# H5 register map
Vendor: Allwinner; Series: H5; File version: 0.1
CPU: 0, little endian, MPU, no FPU, 0 interrupt priority bits
Registers are 32-bit, read-write, reset 0x0 unless marked. A register's access mark holds for its fields unless they carry their own. Offsets are from the block's base; [hi:lo] are bit positions; lines under a group give offsets from that group; {n}, {i} and the like mark numbered series.

## TSC
Base 0x01C06000
Same registers: TSG 0x01C06040, TSF0 0x01C06100, TSD0 0x01C06180, TSF1 0x01C06200, TSD1 0x01C06280, TSF2 0x01C06300, TSD2 0x01C06380, TSF3 0x01C06400, TSD3 0x01C06480, TSF4 0x01C06500, TSD4 0x01C06580
0x00 TSC group
  0x00 TSC_CTLR reset not defined — TSC Control Register
  0x04 TSC_STAR reset not defined — TSC Status Register
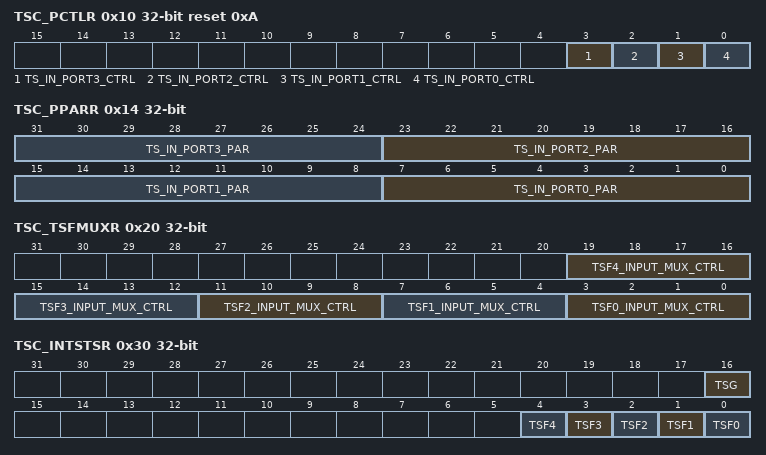
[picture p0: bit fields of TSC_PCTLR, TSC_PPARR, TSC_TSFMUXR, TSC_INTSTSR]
  0x10 TSC_PCTLR reset 0xA — TSC Port Control Register
    [3] TS_IN_PORT3_CTRL — TSInPort3Ctrl TS Input Port3 Control 0: Reserved 1: SSI
      1=SSI
    [2] TS_IN_PORT2_CTRL — TSInPort2Ctrl TS Input Port2 Control 0: SPI 1: SSI
      0=SPI; 1=SSI
    [1] TS_IN_PORT1_CTRL — TSInPort1Ctrl TS Input Port1 Control 0: Reserved 1: SSI
      1=SSI
    [0] TS_IN_PORT0_CTRL — TSInPort0Ctrl TS Input Port0 Control 0: SPI 1: SSI
      0=SPI; 1=SSI
  0x14 TSC_PPARR — TSC Port Parameter Register
    [8n+7:8n] TS_IN_PORT{n}_PAR (n=0..3) — TSInPort{n}Par TS Input Port{n} Parameters Bit Definition 7:5 Reserved 4 SSI data order 0: MSB first for one byte data 1: LSB first for one byte data 3 CLOCK signal polarity 0: Rise edge capturing 1: Fall edge capturing 2 ERROR signal polarity 0: High level active 1: Low level active 1 DVALID signal polarity 0: High level active 1: Low level active 0 PSYNC signal polarity 0: High level active 1: Low level active
  0x20 TSC_TSFMUXR — TSC TSF Input Multiplex Control Register
    [19:16] TSF4_INPUT_MUX_CTRL — TSF4InputMuxCtrl TSF4 Input Multiplex Control 0000: Data from TSG 0001: Data from TS IN Port0 0010: Data from TS IN Port1 0011: Data from TS IN Port2 0100: Data from TS IN Port3 Others: Reserved
    [15:12] TSF3_INPUT_MUX_CTRL — TSF3InputMuxCtrl TSF3 Input Multiplex Control 0000: Data from TSG 0001: Data from TS IN Port2 0010: Data from TS IN Port3 Others: Reserved
    [11:8] TSF2_INPUT_MUX_CTRL — TSF2InputMuxCtrl TSF2 Input Multiplex Control 0000: Data from TSG 0001: Data from TS IN Port2 Others: Reserved
      0=Data_from_TSG; 1=Data from TS IN Port2 Others: Reserved
    [7:4] TSF1_INPUT_MUX_CTRL — TSF1InputMuxCtrl TSF1 Input Multiplex Control 0000: Data from TSG 0001: Data from TS IN Port0 0010: Data from TS IN Port1 Others: Reserved
    [3:0] TSF0_INPUT_MUX_CTRL — TSF0InputMuxCtrl TSF0 Input Multiplex Control 0000: Data from TSG 0001: Data from TS IN Port0 Others: Reserved
      0=Data_from_TSG; 1=Data from TS IN Port0 Others: Reserved
  0x28 TSC_OUTMUXR reset not defined — TSC Port Output Multiplex Control Register
  0x30 TSC_INTSTSR — TSC Interrupt Status Register
    [16] TSG ro — Interrupt Global Status When all TSG interrupt status bits are cleared,the bit will be cleared by hardware.
    [n] TSF{n} ro (n=0..4) — Interrupt Global Status When all TSF{n} interrupt status bits are cleared,the bit will be cleared by hardware.
0x00 TSD group
  0x00 TSD_CTLR — TSD Control Register
    [1:0] DESC_ARITH — DescArith Descramble Arithmetic 00: DVB CSA V1.1 Others: Reserved
      0=DVB (DVB CSA V1.1 Others: Reserved)
  0x04 TSD_STAR reset not defined — TSD Status Register
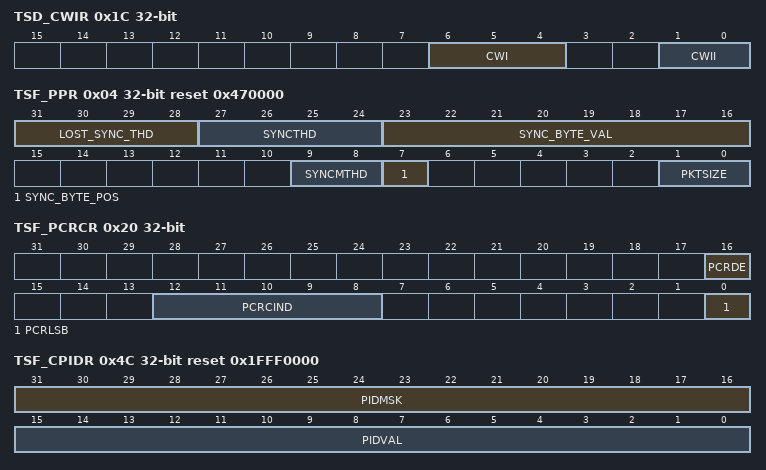
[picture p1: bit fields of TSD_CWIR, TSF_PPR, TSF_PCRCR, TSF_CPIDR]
  0x1C TSD_CWIR — TSD Control Word Index Register
    [6:4] CWI — Control Word Index This value is the Control index for Control word access. Range is from 0x0 to 0x7.
    [1:0] CWII — Control Word Internal Index 00: Odd Control Word Low 32-bit, OCW[31:0] 01: Odd Control Word High 32-bit, OCW[63:32] 10: Even Control Word Low 32-bit, ECW[31:0] 11: Even Control Word High 32-bit, ECW[63:0]
      0=Odd Control Word Low 32-bit, OCW[31:0]; 1=Odd Control Word High 32-bit, OCW[63:32]; 2=Even Control Word Low 32-bit, ECW[31:0]; 3=Even Control Word High 32-bit, ECW[63:0]
  0x20 TSD_CWR — TSD Control Word Register
    [31:0] CWD — Content of Control Word corresponding to the TSD_CWIR value
0x00 TSF group
  0x04 TSF_PPR reset 0x470000 — TSF Packet Parameter Register
    [31:28] LOST_SYNC_THD — LostSyncThd Lost Sync Packet Threshold It is used for packet sync lost by checking the value of sync byte.
    [27:24] SYNCTHD — SyncThd Sync Packet Threshold It is used for packet sync by checking the value of sync byte.
    [23:16] SYNC_BYTE_VAL — SyncByteVal Sync Byte Value This is the value of sync byte used in the TS Packet.
    [9:8] SYNCMTHD — SyncMthd Packet Sync Method 00: By PSYNC signal 01: By Sync byte 10: By both PSYNC and Sync Byte 11: Reserved
      0=By PSYNC signal; 1=By Sync byte; 2=By both PSYNC and Sync Byte
    [7] SYNC_BYTE_POS — SyncBytePos Sync Byte Position 0: The 1st byte position 1: The 5th byte position Note: This bit is only used for 192 bytes packet size.
      0=_1st (The 1st byte position); 1=_5th (The 5th byte position Note: This bit is only used for 192 bytes packet size.)
    [1:0] PKTSIZE — PktSize Packet Size Byte Size for one TS packet 00: 188 bytes 01: 192 bytes 10: 204 bytes 11: Reserved
      0=188 bytes; 1=192 bytes; 2=204 bytes
  0x10 TSF_DIER — TSF DMA Interrupt Enable Register
    [31:0] DMAIE — DMA Interrupt Enable DMA interrupt enable bits for channel 0~31.
  0x14 TSF_OIER — TSF Overlap Interrupt Enable Register
    [31:0] OLPIE — Overlap Interrupt Enable Overlap interrupt enable bits for channel 0~31.
  0x18 TSF_DISR — TSF DMA Interrupt Status Register
    [31:0] DMAIS — DMA Interrupt Status DMA interrupt status bits for channel 0~31. Set by hardware, and write 1 to clear it by software. When both these bits and the corresponding DMA Interrupt Enable bits set, the TSF interrupt will generate.
  0x1C TSF_OISR — TSF Overlap Interrupt Status Register
    [31:0] OLPIS — Overlap Interrupt Status Overlap interrupt status bits for channel 0~31. Set ha d a e, a d a e lea ed soft a e iti g . When both these bits and the corresponding Overlap Interrupt Enable bits set, the TSF interrupt will generate.
  0x20 TSF_PCRCR — TSF PCR Control Register
    [16] PCRDE — PCR Detecting Enable 0: Disable 1: Enable
      0=Disable; 1=Enable
    [12:8] PCRCIND — Channel Index m for detecting PCR packet (m from 0 to 31)
    [0] PCRLSB ro — PCR Contest LSB 1 bit PCR[0]
  0x24 TSF_PCRDR — TSF PCR Data Register
    [31:0] PCRMSB ro — PCR Data High 32 bits PCR[33:1]
  0x30 TSF_CENR — TSF Channel Enable Register
    [31:0] FILTEREN_FILTER_ENABLE_FOR_CHANNEL — FilterEn Filter Enable for Channel 0~31 0: Disable 1: Enable From Disable to Enable, internal status of the corresponding filter channel will be reset.
  0x34 TSF_CPER — TSF Channel PES Enable Register
    [31:0] PESEN — PESEn PES Packet Enable for Channel 0~31 0: Disable 1: Enable These bits should not be changed during the corresponding channel enable.
  0x38 TSF_CDER — TSF Channel Descramble Enable Register
    [31:0] DESCEN — DescEn Descramble Enable for Channel 0~31 0: Disable 1: Enable These bits should not be changed during the corresponding channel enable.
  0x3C TSF_CINDR — TSF Channel Index Register
    [4:0] CHIND — Channel Index This value is the channel index for channel private registers access. Range is from 0x00 to 0x1f. Address range of channel private registers is 0x40~0x7f.
  0x40 TSF_CCTLR reset not defined — TSF Channel Control Register
  0x44 TSF_CSTAR reset not defined — TSF Channel Status Register
  0x48 TSF_CCWIR — TSF Channel CW Index Register
    [2:0] CWIND — Related Control Word Index Index to the control word used by this channel when Descramble Enable of this channel enable. This alue is useless he the o espo di g Des a le E a le is .
  0x4C TSF_CPIDR reset 0x1FFF0000 — TSF Channel PID Register
    [31:16] PIDMSK — Filter PID Mask for Channel
    [15:0] PIDVAL — Filter PID value for Channel
  0x50 TSF_CBBAR — TSF Channel Buffer Base Address Register
    [27:0] TSF_BUF_B_ADDR — TSFBufBAddr Data Buffer Base Address for Channel It is 4-word (16Bytes) align address. The LSB four bits should be zero.
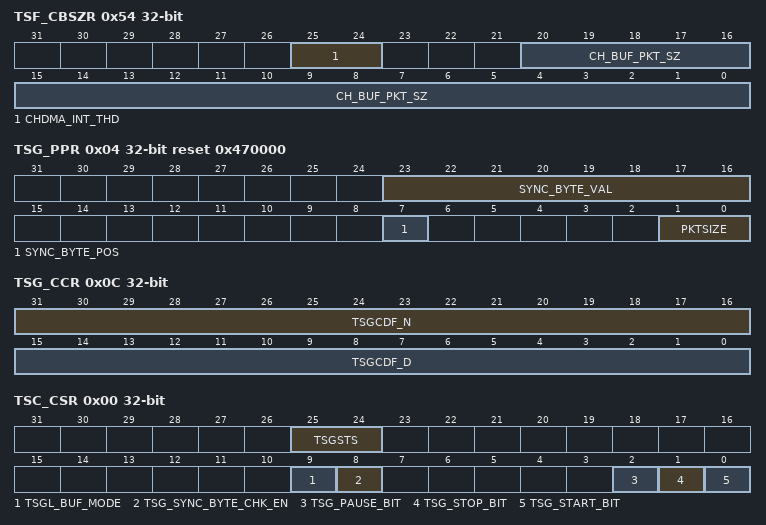
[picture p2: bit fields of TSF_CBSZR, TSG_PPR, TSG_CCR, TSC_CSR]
  0x54 TSF_CBSZR — TSF Channel Buffer Size Register
    [25:24] CHDMA_INT_THD — CHDMAIntThd DMA Interrupt Threshold for Channel The unit is TS packet size. When received packet (has also stored in DRAM) size is beyond (>=) threshold value, the corresponding channel interrupt is generated to CPU. TSC should count the new received packet again, when exceed the specified threshold value, one new interrupt is generated again. 00: 1/2 data buffer packet size 01: 1/4 data buffer packet size 10: 1/8 data buffer packet size 11: 1/16 data buffer packet size
      0=_1_slash_2_data (1/2 data buffer packet size); 1=_1_slash_4_data (1/4 data buffer packet size); 2=_1_slash_8_data (1/8 data buffer packet size); 3=_1_slash_16_data (1/16 data buffer packet size)
    [20:0] CH_BUF_PKT_SZ — CHBufPktSz Data Buffer Packet Size for Channel The exact buffer size of buffer is N+1 bytes. The maximum buffer size is 2MB. This size should be 4-word (16Bytes) aligned. The LSB four bits should be zero.
  0x58 TSF_CBWPR — TSF Channel Buffer Write Pointer Register
    [20:0] BUFWRPTR — BufWrPtr Data Buffer Write Pointer (in Bytes) This value is changed by hardware, when data is filled into buffer, this pointer is increased. And this pointer can be set by software, but it should not be changed by software during the corresponding channel is enabled.
  0x5C TSF_CBRPR — TSF Channel Buffer Read Pointer Register
    [20:0] BUFRDPTR — BufRdPtr Data Buffer Read Pointer (in Bytes) This pointer should be changed by software after the data of buffer is read.
0x00 TSG group
  0x04 TSG_PPR reset 0x470000 — TSG Packet Parameter Register
    [23:16] SYNC_BYTE_VAL — SyncByteVal Sync Byte Value This is the value of sync byte used in the TS Packet.
    [7] SYNC_BYTE_POS — SyncBytePos Sync Byte Position 0: the 1st byte position 1: the 5th byte position Note: This bit is only used for 192 bytes packet size.
      0=_1st (the 1st byte position); 1=_5th (the 5th byte position Note: This bit is only used for 192 bytes packet size.)
    [1:0] PKTSIZE — PktSize Packet Size Byte Size for one TS packet 0: 188 bytes Others: Reserved
  0x0C TSG_CCR — TSG Clock Control Register
    [31:16] TSGCDF_N — TSG Clock Divide Factor (N) The Numerator part of TSG Clock Divisor Factor.
    [15:0] TSGCDF_D — TSG Clock Divide Factor (D) The Denominator part of TSG Clock Divisor Factor. Frequency of output clock: Fo = (Fi*(N+1))/(8*(D+1)). Fi is the input special clock of TSC, and D must not less than N.
  0x10 TSG_BBAR — TSG Buffer Base Address Register
    [31:0] TSG_BUF_BASE — TSGBufBase Buffer Base Address This value is a start address of TSG buffer. Note: This value should be 4-word (16Bytes) align, and the lowest 4 bits of this value should be zero.
  0x14 TSG_BSZR — TSG Buffer Size Register
    [23:0] TSG_BUF_SIZE — TSGBufSize Data Buffer Size for TS Generator It is in byte unit. The size should be 4-word (16Bytes) align, and the lowest 4 bits should be zero.
  0x18 TSG_BPR — TSG Buffer Pointer Register
    [23:0] TSG_BUF_PTR ro — TSGBufPtr Data Buffer Pointer for TS Generator Current TS generator data buffer read pointer (in byte unit)
0x00 TSC_CSR
  [25:24] TSGSTS ro — TSGSts Status for TS Generator 00: IDLE state 01: Running state 10: PAUSE state Others: Reserved
    0=IDLE (IDLE state); 1=Running state; 2=PAUSE (PAUSE state Others: Reserved)
  [9] TSGL_BUF_MODE — TSGLBufMode Loop Buffer Mode Whe set to , the TSG e te al uffe is i loop ode.
  [8] TSG_SYNC_BYTE_CHK_EN — TSGSyncByteChkEn Sync Byte Check Enable Enable/Disable check SYNC byte for receiving new packet 0: Disable 1: Enable If enable check SYNC byte and an error SYNC byte is receiver, TS Generator would come into PAUSE state. If the correspond interrupt is enable, the interrupt would happen.
    0=Disable; 1=Enable If enable check SYNC byte and an error SYNC byte is receiver, TS Generator would come into PAUSE state. If the correspond interrupt is enable, the interrupt would happen.
  [2] TSG_PAUSE_BIT — TSGPauseBit Pause Bit for TS Generator W ite to pause TS Generator. TS Generator would stop fetch new data from DRAM. After finishing this operation, this bit will clear to zero by ha d a e. I PAUSE state, ite to esu e this state.
  [1] TSG_STOP_BIT — TSGStopBit Stop Bit for TS Generator W ite to s top TS Generator. TS Generator would stop fetch new data from DRAM. The data already in its FIFO should be sent to TS filter. After finishing this operation, this bit will clear to zero by hardware.
  [0] TSG_START_BIT — TSGStartBit Start Bit for TS Generator Write to sta t TS Ge e ato . TS Ge e ato ould fet h data f o DRAM and generate SPI stream to TS filter. This bit will clear to zero by hardware after TS Generator is running.
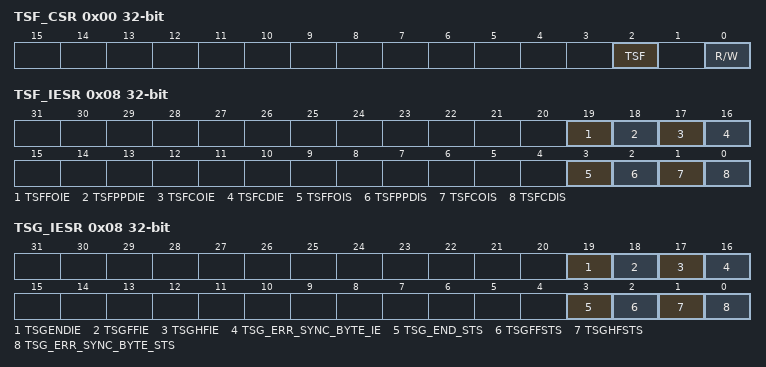
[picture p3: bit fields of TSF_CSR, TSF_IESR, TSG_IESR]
0x00 TSF_CSR
  [2] TSF — Enable 0: Disable TSF Input 1: Enable TSF Input
    0=Disable TSF Input; 1=Enable TSF Input
  [0] R/W — 0 TSFGSR TSF Global Soft Reset W iti g by software will reset all status and state machine of TSF. And it is cleared by hardware after reset. W iti g by software has no effect.
0x08 TSF_IESR
  [19] TSFFOIE — TS PID Filter (TSF) Internal FIFO Overrun Interrupt Enable 0: Disable 1: Enable
    0=Disable; 1=Enable
  [18] TSFPPDIE — TS PCR Packet Detect Interrupt Enable 0: Disable 1: Enable
    0=Disable; 1=Enable
  [17] TSFCOIE — TS PID Filter (TSF) Channel Overlap Interrupt Global Enable 0: Disable 1: Enable
    0=Disable; 1=Enable
  [16] TSFCDIE — TS PID Filter (TSF) Channel DMA Interrupt Global Enable 0: Disable 1: Enable
    0=Disable; 1=Enable
  [3] TSFFOIS — TS PID Filter (TSF) Internal FIFO Overrun Status W ite to lea it.
  [2] TSFPPDIS — TS PCR Packet Found Status Whe it is , o e TS PCR Pa ket is fou d. W ite to lea it.
  [1] TSFCOIS ro — TS PID Filter (TSF) Channel Overlap Status It is global status for 32 channel. It would clear to zero after all channels status bits are cleared.
  [0] TSFCDIS ro — TS PID Filter (TSF) Channel DMA status It is global status for 32 channel. It would clear to zero after all channels status bits are cleared.
0x08 TSG_IESR
  [19] TSGENDIE — TSGEndIE TS Generator (TSG) End Interrupt Enable 0: Disable 1: Enable If set this bit, the interrupt would assert to CPU when all data in external DRAM are sent to TS PID filter.
    0=Disable; 1=Enable If set this bit, the interrupt would assert to CPU when all data in external DRAM are sent to TS PID filter
  [18] TSGFFIE — TS Generator (TSG) Full Finish Interrupt Enable 0: Disable 1: Enable
    0=Disable; 1=Enable
  [17] TSGHFIE — TS Generator (TSG) Half Finish Interrupt Enable 0: Disable 1: Enable
    0=Disable; 1=Enable
  [16] TSG_ERR_SYNC_BYTE_IE — TSGErrSyncByteIE TS Generator (TSG) Error Sync Byte Interrupt Enable 0: Disable 1: Enable
    0=Disable; 1=Enable
  [3] TSG_END_STS — TSGEndSts TS Generator (TSG) End Status W ite to lea it.
  [2] TSGFFSTS — TSGFFSts TS Generator (TSG) Full Finish Status W ite to lea it.
  [1] TSGHFSTS — TSGHFSts TS Generator (TSG) Half Finish Status W ite to lea it.
  [0] TSG_ERR_SYNC_BYTE_STS — TSGErrSyncByteSts TS Generator (TSG) Error Sync Byte Status W ite to lea it.
